# RL6678_IP_SVD register map
Vendor: Realtek
Registers are 32-bit, read-write, reset 0x0 unless marked. A register's access mark holds for its fields unless they carry their own. Offsets are from the block's base; [hi:lo] are bit positions; {n}, {i} and the like mark numbered series.

## AUD_REG
Base 0x4100C100
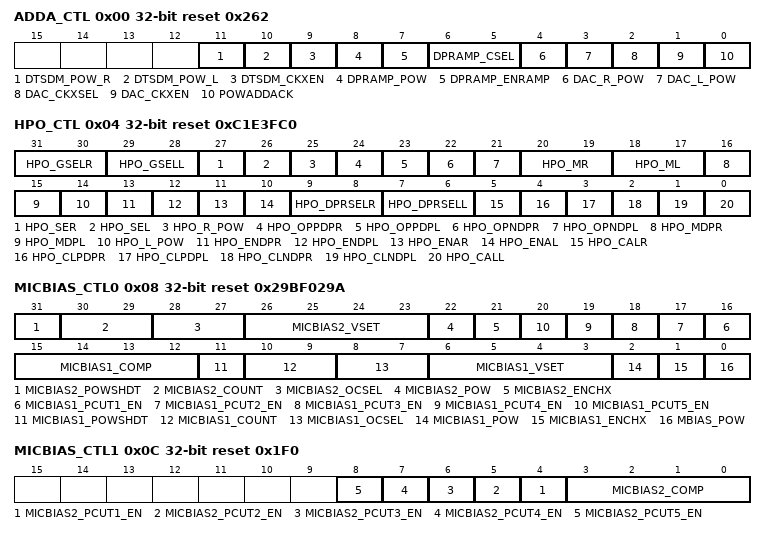
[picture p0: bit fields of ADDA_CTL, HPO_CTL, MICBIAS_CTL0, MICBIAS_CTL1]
0x00 ADDA_CTL reset 0x262 — ADC And DAC Control Register
  [11] DTSDM_POW_R — Right channel ADC power on control: 0: power down 1: power on
  [10] DTSDM_POW_L — Left channel ADC power on control: 0: power down 1: power on
  [9] DTSDM_CKXEN — ADC integrater 1 OP chopper enable: 0 : disable 1 : enable (default)
  [8] DPRAMP_POW — DPRAMP power down control (0: power down, 1: power on)
  [7] DPRAMP_ENRAMP — DPRAMP enable ramp control (0: disable, 1: enable)
  [6:5] DPRAMP_CSEL — Depop C size selection (00: 1x, 01: 2x, 10: 3x, 11: 4x)
  [4] DAC_R_POW — DAC right channel power down control (0: power down, 1: power on)
  [3] DAC_L_POW — DAC left channel power down control (0: power down, 1: power on)
  [2] DAC_CKXSEL — DAC chopper clock selection (0: ckx2/4, 1: ckx2/8)
  [1] DAC_CKXEN — DAC chopper clock enable control (0: disable, 1: enable)
  [0] POWADDACK — AD/DA clock power down control (0: power down, 1: power on)
0x04 HPO_CTL reset 0xC1E3FC0 — Headphone Out Control Register
  [31:30] HPO_GSELR — HPO gain conrtol
  [29:28] HPO_GSELL — HPO gain conrtol
  [27] HPO_SER — Headphone right channel single-end mode control (0: differential, 1: single-end)
  [26] HPO_SEL — Headphone left channel single-end mode control (0: differential, 1: single-end)
  [25] HPO_R_POW — Headphone right channel power down control (0: power down, 1: power on)
  [24] HPO_OPPDPR — Headphone right channel op positive depop mode control (0: no depop, 1: depop)
  [23] HPO_OPPDPL — Headphone left channel op positive depop mode control (0: no depop, 1: depop)
  [22] HPO_OPNDPR — Headphone right channel op negative depop mode control (0: no depop, 1: depop)
  [21] HPO_OPNDPL — Headphone left channel op negative depop mode control (0: no depop, 1: depop)
  [20:19] HPO_MR — Headphone right channel mute control (0: un-mute, 1: mute). HPO_MR[0]: DAC mute control, HPO_MR[1]: Analog in mute control
  [18:17] HPO_ML — Headphone left channel mute control (0: un-mute, 1: mute). HPO_ML[0]: DAC mute control, HPO_ML[1]: Analog in mute control
  [16] HPO_MDPR — Headphone right channel mute depop mode control (0: no depop, 1: depop)
  [15] HPO_MDPL — Headphone left channel mute depop mode control (0: no depop, 1: depop)
  [14] HPO_L_POW — Headphone left channel power down control (0: power down, 1: power on)
  [13] HPO_ENDPR — Headphone right channel enable depop control (0: disable, 1: enable)
  [12] HPO_ENDPL — Headphone left channel enable depop control (0: disable, 1: enable)
  [11] HPO_ENAR — Headphone right channel enable amplifier control (0: disable, 1: enable)
  [10] HPO_ENAL — Headphone left channel enable amplifier control (0: disable, 1: enable)
  [9:8] HPO_DPRSELR — Headphone right channel depop R size selection (00: 1x, 01: 2x, 10: 3x, 11: 4x)
  [7:6] HPO_DPRSELL — Headphone left channel depop R size selection (00: 1x, 01: 2x, 10: 3x, 11: 4x)
  [5] HPO_CALR — Headphone right channel capless mode control (0: non-capless, 1: capless)
  [4] HPO_CLPDPR — Headphone right channel capless positive depop mode control (0: no depop, 1: depop)
  [3] HPO_CLPDPL — Headphone left channel capless positive depop mode control (0: no depop, 1: depop)
  [2] HPO_CLNDPR — Headphone right channel capless negative depop mode control (0: no depop, 1: depop)
  [1] HPO_CLNDPL — Headphone left channel capless negative depop mode control (0: no depop, 1: depop)
  [0] HPO_CALL — Headphone left channel capless mode control (0: non-capless, 1: capless)
0x08 MICBIAS_CTL0 reset 0x29BF029A — MICBIAS Control Register 0
  [31] MICBIAS2_POWSHDT — MICMIAS OCP power control 0: disable OCP 1: enable OCP
  [30:29] MICBIAS2_COUNT — when OCP happen disable time @312.5kHz 00: 819.2us 01: 1638.4us 10: 3276.8us 11: 6553.6us
  [28:27] MICBIAS2_OCSEL — OCP current selection 00: 2.5mA 01: 5mA 10: 7.5mA 11: 10mA
  [26:23] MICBIAS2_VSET — MICBIAS select output voltage level 0.1V per step 0000:1.15V 0001:1.25V 0010:1.35V 0011:1.45V 0100:1.55V 0101:1.65V 0110:1.75V 0111:1.8V
  [22] MICBIAS2_POW — MICBIAS power control 0:power down 1:power on
  [21] MICBIAS2_ENCHX — MICBIAS enable chopper clock 0:disable 1:enable
  [n+15] MICBIAS1_PCUT{n}_EN (n=1..5) — MICBIAS power cut 0: on 1. off
  [15:12] MICBIAS1_COMP — reserve
  [11] MICBIAS1_POWSHDT — MICBIAS OCP power control 0: disable OCP 1: enable OCP
  [10:9] MICBIAS1_COUNT — when OCP happen disable time @312.5kHz 00: 819.2us 01: 1638.4us 10: 3276.8us 11: 6553.6us
  [8:7] MICBIAS1_OCSEL — OCP current selection 00: 2.5mA 01: 5mA 10: 7.5mA 11: 10mA
  [6:3] MICBIAS1_VSET — MICBIAS select output voltage level 0.1V per step 0000:1.15V 0001:1.25V 0010:1.35V 0011:1.45V 0100:1.55V 0101:1.65V 0110:1.75V 0111:1.8V
  [2] MICBIAS1_POW — MICBIAS power control 0:power down 1:power on
  [1] MICBIAS1_ENCHX — MICBIAS enable chopper clock 0:disable 1:enable
  [0] MBIAS_POW — MBIAS power control 0: power down 1: power on
0x0C MICBIAS_CTL1 reset 0x1F0 — MICBIAS Control Register 1
  [n+3] MICBIAS2_PCUT{n}_EN (n=1..5) — MICBIAS power cut 0: on 1. off
  [3:0] MICBIAS2_COMP — reserved
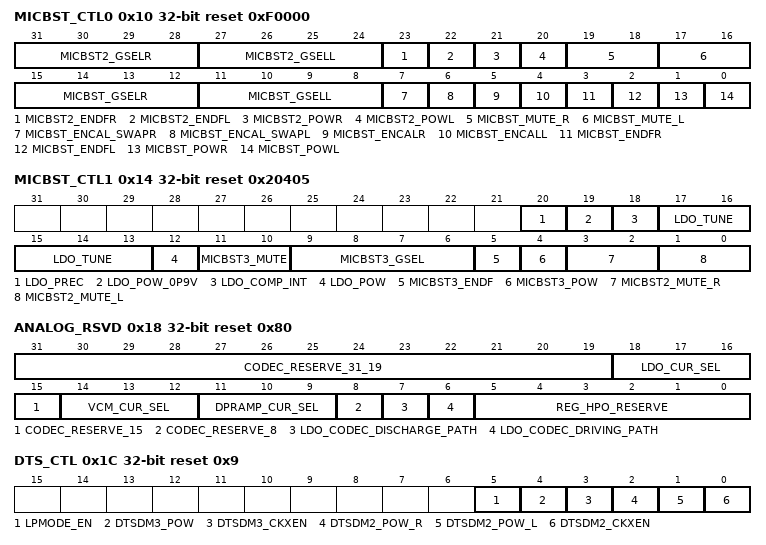
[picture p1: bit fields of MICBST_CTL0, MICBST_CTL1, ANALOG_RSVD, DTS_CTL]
0x10 MICBST_CTL0 reset 0xF0000 — MICBST Control Register 0
  [31:28] MICBST2_GSELR — MICBST right channel gain select 0000: 0dB 0001:5dB 0010:10dB 0011:15dB 0100:20dB 0101:25dB 0110:30dB 0111:35dB 1XXX:40dB
  [27:24] MICBST2_GSELL — MICBST left channel gain select 0000: 0dB 0001:5dB 0010:10dB 0011:15dB 0100:20dB 0101:25dB 0110:30dB 0111:35dB 1XXX:40dB
  [23] MICBST2_ENDFR — MICBST right channel enable differential 0:single to differential 1:differential to differential
  [22] MICBST2_ENDFL — MICBST left channel enable differential 0:single to differential 1:differential to differential
  [21] MICBST2_POWR — MICBST power control right channel 0:power down 1:power on
  [20] MICBST2_POWL — MICBST power control left channel 0:power down 1:power on
  [19:18] MICBST_MUTE_R — MICBST mute control mute<0>: mic in mute<1>: line in 0:unmute 1:mute
  [17:16] MICBST_MUTE_L — MICBST mute control mute<0>: mic in mute<1>: line in 0:unmute 1:mute
  [15:12] MICBST_GSELR — MICBST right channel gain select 0000: 0dB 0001:5dB 0010:10dB 0011:15dB 0100:20dB 0101:25dB 0110:30dB 0111:35dB 1XXX:40dB
  [11:8] MICBST_GSELL — MICBST left channel gain select 0000: 0dB 0001:5dB 0010:10dB 0011:15dB 0100:20dB 0101:25dB 0110:30dB 0111:35dB 1XXX:40dB
  [7] MICBST_ENCAL_SWAPR — MICBST right channel swao_calibratio path 0:disable 1:enable
  [6] MICBST_ENCAL_SWAPL — MICBST left channel swao_calibratio path 0:disable 1:enable
  [5] MICBST_ENCALR — MICBST right channel enable calibration path 0:disable 1:enable
  [4] MICBST_ENCALL — MICBST left channel enable calibration path 0:disable 1:enable
  [3] MICBST_ENDFR — MICBST right channel enable differential 0:single to differential 1:differential to differential
  [2] MICBST_ENDFL — MICBST left channel enable differential 0:single to differential 1:differential to differential
  [1] MICBST_POWR — MICBST power control right channel 0:power down 1:power on
  [0] MICBST_POWL — MICBST power control left channel 0:power down 1:power on
0x14 MICBST_CTL1 reset 0x20405 — MICBST Control Register 1
  [20] LDO_PREC
  [19] LDO_POW_0P9V — LDO Precharge 0: LDO 1: Unity Gain buffer
  [18] LDO_COMP_INT — LDO Miller Compensation 0:close 1:short
  [17:13] LDO_TUNE — LDO voltage control 10000 Vref 0.9V LDO 1.8V
  [12] LDO_POW — LDO power control 0: disable LDO 1: enable LDO
  [11:10] MICBST3_MUTE — MICBST mute control mute: mic in 0:unmute 1:mute
  [9:6] MICBST3_GSEL — MICBST left channel gain select 0000: 0dB 0001:5dB 0010:10dB 0011:15dB 0100:20dB 0101:25dB 0110:30dB 0111:35dB 1XXX:40dB
  [5] MICBST3_ENDF — MICBST left channel enable differential 0:single to differential 1:differential to differential
  [4] MICBST3_POW — MICBST power control left channel 0:power down 1:power on
  [3:2] MICBST2_MUTE_R — MICBST mute control mute: mic in 0:unmute 1:mute
  [1:0] MICBST2_MUTE_L — MICBST mute control mute: mic in 0:unmute 1:mute
0x18 ANALOG_RSVD reset 0x80 — Analog Reserved Register
  [31:19] CODEC_RESERVE_31_19 — reserve
  [18:16] LDO_CUR_SEL — LDO current control: if LPMODE_EN=1 000:1uA 001:1.5uA 010:2uA 011:2.5uA 100 3uA 101:3.5uA 110:4uA 111:4.5uA if LPMODE_EN=0 000:2uA 001:3uA 010:4uA 011:5uA 100 6uA 101:7uA 110:8uA 111:9uA
  [15] CODEC_RESERVE_15 — reserve
  [14:12] VCM_CUR_SEL — DAC VCM Buffer current control: if LPMODE_EN=1 000:1uA 001:1.5uA 010:2uA 011:2.5uA 100 3uA 101:3.5uA 110:4uA 111:4.5uA if LPMODE_EN=0 000:2uA 001:3uA 010:4uA 011:5uA 100 6uA 101:7uA 110:8uA 111:9uA
  [11:9] DPRAMP_CUR_SEL — DPRAMP current control: if LPMODE_EN=1 000:1uA 001:1.5uA 010:2uA 011:2.5uA 100 3uA 101:3.5uA 110:4uA 111:4.5uA if LPMODE_EN=0 000:2uA 001:3uA 010:4uA 011:5uA 100 6uA 101:7uA 110:8uA 111:9uA
  [8] CODEC_RESERVE_8 — reserve
  [7] LDO_CODEC_DISCHARGE_PATH — REG_LDO_DISCHARGE_PATH selection for discharge path of LDO_CODEC 0: discharge path is turn off (default) 1: 1.8kohm discharge path is turned on
  [6] LDO_CODEC_DRIVING_PATH — LDO_CODEC_DRIVING_PATH selection for driving path of LDO_CODEC 0:select strong driving path PMOS w=240um, L=0.44um 1:select 1.8kohm driving path(default)
  [5:0] REG_HPO_RESERVE — REG_HPO_RESERVE<5:0>
0x1C DTS_CTL reset 0x9 — DTS Control Register
  [5] LPMODE_EN — low power mode en 0: disable , current use 12.5uA 1: enable , current use 1uA
  [4] DTSDM3_POW — Left channel ADC power on control: 0: power down 1: power on
  [3] DTSDM3_CKXEN — ADC integrater 1 OP chopper enable: 0 : disable 1 : enable (default)
  [2] DTSDM2_POW_R — Right channel ADC power on control: 0: power down 1: power on
  [1] DTSDM2_POW_L — Left channel ADC power on control: 0: power down 1: power on
  [0] DTSDM2_CKXEN — ADC integrater 1 OP chopper enable: 0 : disable 1 : enable (default)
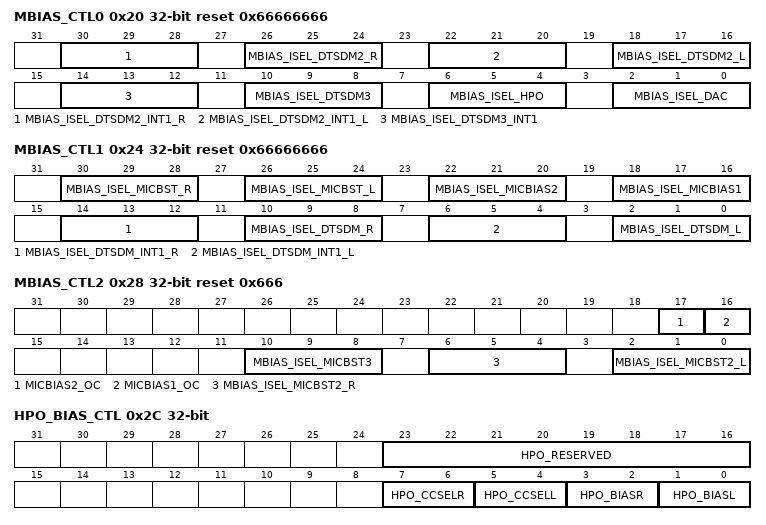
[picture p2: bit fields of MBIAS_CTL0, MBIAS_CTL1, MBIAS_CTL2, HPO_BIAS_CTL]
0x20 MBIAS_CTL0 reset 0x66666666 — MBIAS Control Register 0
  [30:28] MBIAS_ISEL_DTSDM2_INT1_R — DTSDM2_R current control: default 8uA, 1uA per step
  [26:24] MBIAS_ISEL_DTSDM2_R — DTSDM2_R current control: default 4uA, 0.5uA per step
  [22:20] MBIAS_ISEL_DTSDM2_INT1_L — DTSDM2_L current control: default 8uA, 1uA per step
  [18:16] MBIAS_ISEL_DTSDM2_L — DTSDM2_L current control: default 4uA, 0.5uA per step
  [14:12] MBIAS_ISEL_DTSDM3_INT1 — DTSDM3 current control: default 8uA, 1uA per step
  [10:8] MBIAS_ISEL_DTSDM3 — DTSDM3 current control: default 4uA, 0.5uA per step
  [6:4] MBIAS_ISEL_HPO — HPO current control: default 4uA, 0.5uA per step
  [2:0] MBIAS_ISEL_DAC — DAC current control: default 4uA, 0.5uA per step
0x24 MBIAS_CTL1 reset 0x66666666 — MBIAS Control Register 1
  [30:28] MBIAS_ISEL_MICBST_R — MICBST_R current control: default 4uA, 0.5uA per step
  [26:24] MBIAS_ISEL_MICBST_L — MICBST_L current control: default 4uA, 0.5uA per step
  [22:20] MBIAS_ISEL_MICBIAS2 — MICBIAS2 current control: default 4uA, 0.5uA per step
  [18:16] MBIAS_ISEL_MICBIAS1 — MICBIAS1 current control: default 4uA, 0.5uA per step
  [14:12] MBIAS_ISEL_DTSDM_INT1_R — DTSDM1_R current control: default 8uA, 1uA per step
  [10:8] MBIAS_ISEL_DTSDM_R — DTSDM1_R current control: default 4uA, 0.5uA per step
  [6:4] MBIAS_ISEL_DTSDM_INT1_L — DTSDM1_L current control: default 8uA, 1uA per step
  [2:0] MBIAS_ISEL_DTSDM_L — DTSDM1_L current control: default 4uA, 0.5uA per step
0x28 MBIAS_CTL2 access per field reset 0x666 — MBIAS Control Register 2
  [17] MICBIAS2_OC ro
  [16] MICBIAS1_OC ro
  [10:8] MBIAS_ISEL_MICBST3 rw — MICBST3 current control: default 4uA, 0.5uA per step
  [6:4] MBIAS_ISEL_MICBST2_R rw — MICBST2_R current control: default 4uA, 0.5uA per step
  [2:0] MBIAS_ISEL_MICBST2_L rw — MICBST2_L current control: default 4uA, 0.5uA per step
0x2C HPO_BIAS_CTL — Headphone Out Bias Control Register
  [23:16] HPO_RESERVED, [7:6] HPO_CCSELR, [5:4] HPO_CCSELL, [3:2] HPO_BIASR, [1:0] HPO_BIASL
